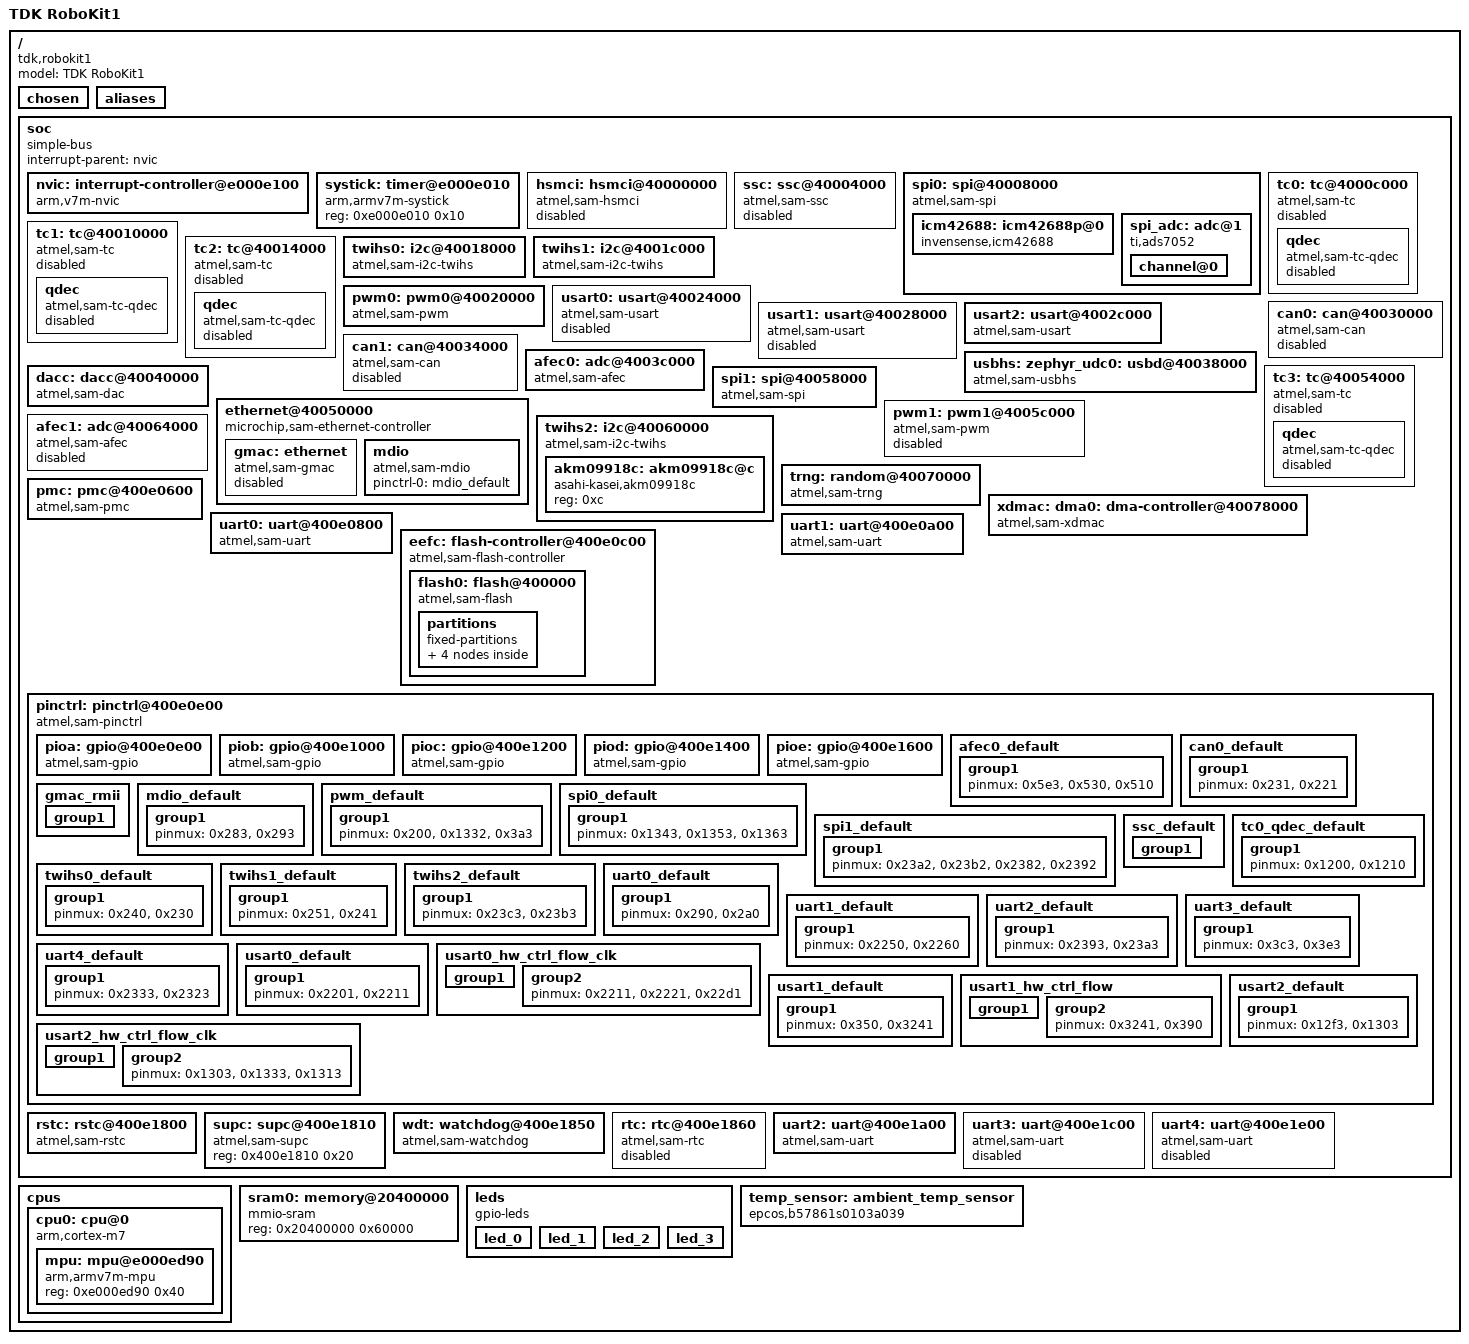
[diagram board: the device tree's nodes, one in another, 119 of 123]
/dts-v1/;

/* node '/' defined in zephyr/dts/common/skeleton.dtsi:9 */
/ {
	#address-cells = < 0x1 >;        /* in zephyr/dts/common/skeleton.dtsi:10 */
	#size-cells = < 0x1 >;           /* in zephyr/dts/common/skeleton.dtsi:11 */
	model = "TDK RoboKit1";          /* in zephyr/boards/tdk/robokit1/robokit1.dts:15 */
	compatible = "tdk,robokit1",
	             "atmel,same70q21b",
	             "atmel,same70";     /* in zephyr/boards/tdk/robokit1/robokit1.dts:16 */

	/* node '/chosen' defined in zephyr/dts/common/skeleton.dtsi:13 */
	chosen {
		zephyr,flash-controller = &eefc;          /* in zephyr/dts/arm/atmel/samx7x.dtsi:22 */
		zephyr,entropy = &trng;                   /* in zephyr/dts/arm/atmel/samx7x.dtsi:23 */
		zephyr,console = &uart2;                  /* in zephyr/boards/tdk/robokit1/robokit1-common.dtsi:19 */
		zephyr,shell-uart = &uart2;               /* in zephyr/boards/tdk/robokit1/robokit1-common.dtsi:20 */
		zephyr,sram = &sram0;                     /* in zephyr/boards/tdk/robokit1/robokit1-common.dtsi:21 */
		zephyr,flash = &flash0;                   /* in zephyr/boards/tdk/robokit1/robokit1-common.dtsi:22 */
		zephyr,code-partition = &slot0_partition; /* in zephyr/boards/tdk/robokit1/robokit1-common.dtsi:23 */
	};

	/* node '/aliases' defined in zephyr/dts/common/skeleton.dtsi:15 */
	aliases {
		watchdog0 = &wdt;             /* in zephyr/dts/arm/atmel/samx7x.dtsi:18 */
		led0 = &led_0;                /* in zephyr/boards/tdk/robokit1/robokit1-common.dtsi:11 */
		magn0 = &akm09918c;           /* in zephyr/boards/tdk/robokit1/robokit1-common.dtsi:12 */
		accel0 = &icm42688;           /* in zephyr/boards/tdk/robokit1/robokit1-common.dtsi:13 */
		die-temp0 = &icm42688;        /* in zephyr/boards/tdk/robokit1/robokit1-common.dtsi:14 */
		ambient-temp0 = &temp_sensor; /* in zephyr/boards/tdk/robokit1/robokit1-common.dtsi:15 */
	};

	/* node '/soc' defined in zephyr/dts/arm/armv7-m.dtsi:6 */
	soc {
		#address-cells = < 0x1 >;     /* in zephyr/dts/arm/armv7-m.dtsi:7 */
		#size-cells = < 0x1 >;        /* in zephyr/dts/arm/armv7-m.dtsi:8 */
		compatible = "simple-bus";    /* in zephyr/dts/arm/armv7-m.dtsi:9 */
		interrupt-parent = < &nvic >; /* in zephyr/dts/arm/armv7-m.dtsi:10 */
		ranges;                       /* in zephyr/dts/arm/armv7-m.dtsi:11 */

		/* node '/soc/interrupt-controller@e000e100' defined in zephyr/dts/arm/armv7-m.dtsi:13 */
		nvic: interrupt-controller@e000e100 {
			#address-cells = < 0x1 >;            /* in zephyr/dts/arm/armv7-m.dtsi:14 */
			compatible = "arm,v7m-nvic";         /* in zephyr/dts/arm/armv7-m.dtsi:15 */
			reg = < 0xe000e100 0xc00 >;          /* in zephyr/dts/arm/armv7-m.dtsi:16 */
			interrupt-controller;                /* in zephyr/dts/arm/armv7-m.dtsi:17 */
			#interrupt-cells = < 0x2 >;          /* in zephyr/dts/arm/armv7-m.dtsi:18 */
			arm,num-irq-priority-bits = < 0x3 >; /* in zephyr/dts/arm/atmel/samx7x.dtsi:488 */
			phandle = < 0x1 >;                   /* in zephyr/dts/arm/armv7-m.dtsi:10 */
		};

		/* node '/soc/timer@e000e010' defined in zephyr/dts/arm/armv7-m.dtsi:21 */
		systick: timer@e000e010 {
			compatible = "arm,armv7m-systick"; /* in zephyr/dts/arm/armv7-m.dtsi:22 */
			reg = < 0xe000e010 0x10 >;         /* in zephyr/dts/arm/armv7-m.dtsi:23 */
		};

		/* node '/soc/hsmci@40000000' defined in zephyr/dts/arm/atmel/samx7x.dtsi:49 */
		hsmci: hsmci@40000000 {
			compatible = "atmel,sam-hsmci"; /* in zephyr/dts/arm/atmel/samx7x.dtsi:50 */
			reg = < 0x40000000 0x4000 >;    /* in zephyr/dts/arm/atmel/samx7x.dtsi:51 */
			clocks = < &pmc 0x2 0x12 >;     /* in zephyr/dts/arm/atmel/samx7x.dtsi:52 */
			status = "disabled";            /* in zephyr/dts/arm/atmel/samx7x.dtsi:53 */
		};

		/* node '/soc/ssc@40004000' defined in zephyr/dts/arm/atmel/samx7x.dtsi:56 */
		ssc: ssc@40004000 {
			compatible = "atmel,sam-ssc"; /* in zephyr/dts/arm/atmel/samx7x.dtsi:57 */
			reg = < 0x40004000 0x4000 >;  /* in zephyr/dts/arm/atmel/samx7x.dtsi:58 */
			interrupts = < 0x16 0x0 >;    /* in zephyr/dts/arm/atmel/samx7x.dtsi:59 */
			clocks = < &pmc 0x2 0x16 >;   /* in zephyr/dts/arm/atmel/samx7x.dtsi:60 */
			status = "disabled";          /* in zephyr/dts/arm/atmel/samx7x.dtsi:61 */
		};

		/* node '/soc/spi@40008000' defined in zephyr/dts/arm/atmel/samx7x.dtsi:64 */
		spi0: spi@40008000 {
			compatible = "atmel,sam-spi";  /* in zephyr/dts/arm/atmel/samx7x.dtsi:65 */
			#address-cells = < 0x1 >;      /* in zephyr/dts/arm/atmel/samx7x.dtsi:66 */
			#size-cells = < 0x0 >;         /* in zephyr/dts/arm/atmel/samx7x.dtsi:67 */
			reg = < 0x40008000 0x4000 >;   /* in zephyr/dts/arm/atmel/samx7x.dtsi:68 */
			interrupts = < 0x15 0x0 >;     /* in zephyr/dts/arm/atmel/samx7x.dtsi:69 */
			clocks = < &pmc 0x2 0x15 >;    /* in zephyr/dts/arm/atmel/samx7x.dtsi:70 */
			pinctrl-0 = < &spi0_default >; /* in zephyr/boards/tdk/robokit1/robokit1-common.dtsi:100 */
			pinctrl-names = "default";     /* in zephyr/boards/tdk/robokit1/robokit1-common.dtsi:101 */
			dmas = < &xdmac 0x0 0x1 >,
			       < &xdmac 0x1 0x2 >;     /* in zephyr/boards/tdk/robokit1/robokit1-common.dtsi:102 */
			dma-names = "tx",
			            "rx";              /* in zephyr/boards/tdk/robokit1/robokit1-common.dtsi:103 */
			cs-gpios = < &pioa 0x1f 0x1 >,
			           < &pioc 0x1f 0x1 >; /* in zephyr/boards/tdk/robokit1/robokit1-common.dtsi:104 */
			status = "okay";               /* in zephyr/boards/tdk/robokit1/robokit1-common.dtsi:106 */

			/* node '/soc/spi@40008000/icm42688p@0' defined in zephyr/boards/tdk/robokit1/robokit1-common.dtsi:108 */
			icm42688: icm42688p@0 {
				compatible = "invensense,icm42688",
				             "invensense,icm4268x"; /* in zephyr/boards/tdk/robokit1/robokit1-common.dtsi:109 */
				reg = < 0x0 >;                      /* in zephyr/boards/tdk/robokit1/robokit1-common.dtsi:110 */
				int-gpios = < &pioc 0x5 0x0 >;      /* in zephyr/boards/tdk/robokit1/robokit1-common.dtsi:111 */
				spi-max-frequency = < 0x16e3600 >;  /* in zephyr/boards/tdk/robokit1/robokit1-common.dtsi:112 */
				accel-pwr-mode = < 0x3 >;           /* in zephyr/boards/tdk/robokit1/robokit1-common.dtsi:113 */
				accel-odr = < 0x5 >;                /* in zephyr/boards/tdk/robokit1/robokit1-common.dtsi:114 */
				accel-fs = < 0x0 >;                 /* in zephyr/boards/tdk/robokit1/robokit1-common.dtsi:115 */
				gyro-pwr-mode = < 0x3 >;            /* in zephyr/boards/tdk/robokit1/robokit1-common.dtsi:116 */
				gyro-odr = < 0x5 >;                 /* in zephyr/boards/tdk/robokit1/robokit1-common.dtsi:117 */
				gyro-fs = < 0x0 >;                  /* in zephyr/boards/tdk/robokit1/robokit1-common.dtsi:118 */
			};

			/* node '/soc/spi@40008000/adc@1' defined in zephyr/boards/tdk/robokit1/robokit1-common.dtsi:121 */
			spi_adc: adc@1 {
				compatible = "ti,ads7052";         /* in zephyr/boards/tdk/robokit1/robokit1-common.dtsi:122 */
				reg = < 0x1 >;                     /* in zephyr/boards/tdk/robokit1/robokit1-common.dtsi:123 */
				#io-channel-cells = < 0x1 >;       /* in zephyr/boards/tdk/robokit1/robokit1-common.dtsi:124 */
				#address-cells = < 0x1 >;          /* in zephyr/boards/tdk/robokit1/robokit1-common.dtsi:125 */
				#size-cells = < 0x0 >;             /* in zephyr/boards/tdk/robokit1/robokit1-common.dtsi:126 */
				spi-max-frequency = < 0x16e3600 >; /* in zephyr/boards/tdk/robokit1/robokit1-common.dtsi:127 */
				phandle = < 0x13 >;                /* in zephyr/boards/tdk/robokit1/robokit1-common.dtsi:52 */

				/* node '/soc/spi@40008000/adc@1/channel@0' defined in zephyr/boards/tdk/robokit1/robokit1-common.dtsi:129 */
				channel@0 {
					reg = < 0x0 >;                      /* in zephyr/boards/tdk/robokit1/robokit1-common.dtsi:130 */
					zephyr,gain = "ADC_GAIN_1";         /* in zephyr/boards/tdk/robokit1/robokit1-common.dtsi:131 */
					zephyr,reference = "ADC_REF_VDD_1"; /* in zephyr/boards/tdk/robokit1/robokit1-common.dtsi:132 */
					zephyr,vref-mv = < 0xce4 >;         /* in zephyr/boards/tdk/robokit1/robokit1-common.dtsi:133 */
					zephyr,acquisition-time = < 0x0 >;  /* in zephyr/boards/tdk/robokit1/robokit1-common.dtsi:134 */
					zephyr,resolution = < 0xe >;        /* in zephyr/boards/tdk/robokit1/robokit1-common.dtsi:135 */
				};
			};
		};

		/* node '/soc/tc@4000c000' defined in zephyr/dts/arm/atmel/samx7x.dtsi:74 */
		tc0: tc@4000c000 {
			compatible = "atmel,sam-tc";                 /* in zephyr/dts/arm/atmel/samx7x.dtsi:75 */
			reg = < 0x4000c000 0x100 >;                  /* in zephyr/dts/arm/atmel/samx7x.dtsi:76 */
			interrupts = < 0x17 0x0 0x18 0x0 0x19 0x0 >; /* in zephyr/dts/arm/atmel/samx7x.dtsi:77 */
			clocks = < &pmc 0x2 0x17 >,
			         < &pmc 0x2 0x18 >,
			         < &pmc 0x2 0x19 >;                  /* in zephyr/dts/arm/atmel/samx7x.dtsi:80 */
			status = "disabled";                         /* in zephyr/dts/arm/atmel/samx7x.dtsi:83 */

			/* node '/soc/tc@4000c000/qdec' defined in zephyr/dts/arm/atmel/samx7x.dtsi:85 */
			qdec {
				compatible = "atmel,sam-tc-qdec"; /* in zephyr/dts/arm/atmel/samx7x.dtsi:86 */
				status = "disabled";              /* in zephyr/dts/arm/atmel/samx7x.dtsi:87 */
			};
		};

		/* node '/soc/tc@40010000' defined in zephyr/dts/arm/atmel/samx7x.dtsi:91 */
		tc1: tc@40010000 {
			compatible = "atmel,sam-tc";                 /* in zephyr/dts/arm/atmel/samx7x.dtsi:92 */
			reg = < 0x40010000 0x100 >;                  /* in zephyr/dts/arm/atmel/samx7x.dtsi:93 */
			interrupts = < 0x1a 0x0 0x1b 0x0 0x1c 0x0 >; /* in zephyr/dts/arm/atmel/samx7x.dtsi:94 */
			clocks = < &pmc 0x2 0x1a >,
			         < &pmc 0x2 0x1b >,
			         < &pmc 0x2 0x1c >;                  /* in zephyr/dts/arm/atmel/samx7x.dtsi:97 */
			status = "disabled";                         /* in zephyr/dts/arm/atmel/samx7x.dtsi:100 */

			/* node '/soc/tc@40010000/qdec' defined in zephyr/dts/arm/atmel/samx7x.dtsi:102 */
			qdec {
				compatible = "atmel,sam-tc-qdec"; /* in zephyr/dts/arm/atmel/samx7x.dtsi:103 */
				status = "disabled";              /* in zephyr/dts/arm/atmel/samx7x.dtsi:104 */
			};
		};

		/* node '/soc/tc@40014000' defined in zephyr/dts/arm/atmel/samx7x.dtsi:108 */
		tc2: tc@40014000 {
			compatible = "atmel,sam-tc";                 /* in zephyr/dts/arm/atmel/samx7x.dtsi:109 */
			reg = < 0x40014000 0x100 >;                  /* in zephyr/dts/arm/atmel/samx7x.dtsi:110 */
			interrupts = < 0x2f 0x0 0x30 0x0 0x31 0x0 >; /* in zephyr/dts/arm/atmel/samx7x.dtsi:111 */
			clocks = < &pmc 0x2 0x2f >,
			         < &pmc 0x2 0x30 >,
			         < &pmc 0x2 0x31 >;                  /* in zephyr/dts/arm/atmel/samx7x.dtsi:114 */
			status = "disabled";                         /* in zephyr/dts/arm/atmel/samx7x.dtsi:117 */

			/* node '/soc/tc@40014000/qdec' defined in zephyr/dts/arm/atmel/samx7x.dtsi:119 */
			qdec {
				compatible = "atmel,sam-tc-qdec"; /* in zephyr/dts/arm/atmel/samx7x.dtsi:120 */
				status = "disabled";              /* in zephyr/dts/arm/atmel/samx7x.dtsi:121 */
			};
		};

		/* node '/soc/i2c@40018000' defined in zephyr/dts/arm/atmel/samx7x.dtsi:125 */
		twihs0: i2c@40018000 {
			compatible = "atmel,sam-i2c-twihs"; /* in zephyr/dts/arm/atmel/samx7x.dtsi:126 */
			clock-frequency = < 0x186a0 >;      /* in zephyr/dts/arm/atmel/samx7x.dtsi:127 */
			#address-cells = < 0x1 >;           /* in zephyr/dts/arm/atmel/samx7x.dtsi:128 */
			#size-cells = < 0x0 >;              /* in zephyr/dts/arm/atmel/samx7x.dtsi:129 */
			reg = < 0x40018000 0x12b >;         /* in zephyr/dts/arm/atmel/samx7x.dtsi:130 */
			interrupts = < 0x13 0x0 >;          /* in zephyr/dts/arm/atmel/samx7x.dtsi:131 */
			clocks = < &pmc 0x2 0x13 >;         /* in zephyr/dts/arm/atmel/samx7x.dtsi:132 */
			pinctrl-0 = < &twihs0_default >;    /* in zephyr/boards/tdk/robokit1/robokit1-common.dtsi:75 */
			pinctrl-names = "default";          /* in zephyr/boards/tdk/robokit1/robokit1-common.dtsi:76 */
			status = "okay";                    /* in zephyr/boards/tdk/robokit1/robokit1-common.dtsi:77 */
		};

		/* node '/soc/i2c@4001c000' defined in zephyr/dts/arm/atmel/samx7x.dtsi:136 */
		twihs1: i2c@4001c000 {
			compatible = "atmel,sam-i2c-twihs"; /* in zephyr/dts/arm/atmel/samx7x.dtsi:137 */
			clock-frequency = < 0x186a0 >;      /* in zephyr/dts/arm/atmel/samx7x.dtsi:138 */
			#address-cells = < 0x1 >;           /* in zephyr/dts/arm/atmel/samx7x.dtsi:139 */
			#size-cells = < 0x0 >;              /* in zephyr/dts/arm/atmel/samx7x.dtsi:140 */
			reg = < 0x4001c000 0x12b >;         /* in zephyr/dts/arm/atmel/samx7x.dtsi:141 */
			interrupts = < 0x14 0x0 >;          /* in zephyr/dts/arm/atmel/samx7x.dtsi:142 */
			clocks = < &pmc 0x2 0x14 >;         /* in zephyr/dts/arm/atmel/samx7x.dtsi:143 */
			pinctrl-0 = < &twihs1_default >;    /* in zephyr/boards/tdk/robokit1/robokit1-common.dtsi:81 */
			pinctrl-names = "default";          /* in zephyr/boards/tdk/robokit1/robokit1-common.dtsi:82 */
			status = "okay";                    /* in zephyr/boards/tdk/robokit1/robokit1-common.dtsi:83 */
		};

		/* node '/soc/pwm0@40020000' defined in zephyr/dts/arm/atmel/samx7x.dtsi:147 */
		pwm0: pwm0@40020000 {
			compatible = "atmel,sam-pwm"; /* in zephyr/dts/arm/atmel/samx7x.dtsi:148 */
			reg = < 0x40020000 0x4000 >;  /* in zephyr/dts/arm/atmel/samx7x.dtsi:149 */
			interrupts = < 0x1f 0x0 >;    /* in zephyr/dts/arm/atmel/samx7x.dtsi:150 */
			clocks = < &pmc 0x2 0x1f >;   /* in zephyr/dts/arm/atmel/samx7x.dtsi:151 */
			prescaler = < 0xa >;          /* in zephyr/dts/arm/atmel/samx7x.dtsi:153 */
			divider = < 0x1 >;            /* in zephyr/dts/arm/atmel/samx7x.dtsi:154 */
			#pwm-cells = < 0x3 >;         /* in zephyr/dts/arm/atmel/samx7x.dtsi:155 */
			pinctrl-0 = < &pwm_default >; /* in zephyr/boards/tdk/robokit1/robokit1-common.dtsi:190 */
			pinctrl-names = "default";    /* in zephyr/boards/tdk/robokit1/robokit1-common.dtsi:191 */
			status = "okay";              /* in zephyr/boards/tdk/robokit1/robokit1-common.dtsi:192 */
		};

		/* node '/soc/usart@40024000' defined in zephyr/dts/arm/atmel/samx7x.dtsi:158 */
		usart0: usart@40024000 {
			compatible = "atmel,sam-usart"; /* in zephyr/dts/arm/atmel/samx7x.dtsi:159 */
			reg = < 0x40024000 0x100 >;     /* in zephyr/dts/arm/atmel/samx7x.dtsi:160 */
			interrupts = < 0xd 0x0 >;       /* in zephyr/dts/arm/atmel/samx7x.dtsi:161 */
			clocks = < &pmc 0x2 0xd >;      /* in zephyr/dts/arm/atmel/samx7x.dtsi:162 */
			status = "disabled";            /* in zephyr/dts/arm/atmel/samx7x.dtsi:163 */
		};

		/* node '/soc/usart@40028000' defined in zephyr/dts/arm/atmel/samx7x.dtsi:166 */
		usart1: usart@40028000 {
			compatible = "atmel,sam-usart"; /* in zephyr/dts/arm/atmel/samx7x.dtsi:167 */
			reg = < 0x40028000 0x100 >;     /* in zephyr/dts/arm/atmel/samx7x.dtsi:168 */
			interrupts = < 0xe 0x0 >;       /* in zephyr/dts/arm/atmel/samx7x.dtsi:169 */
			clocks = < &pmc 0x2 0xe >;      /* in zephyr/dts/arm/atmel/samx7x.dtsi:170 */
			status = "disabled";            /* in zephyr/dts/arm/atmel/samx7x.dtsi:171 */
		};

		/* node '/soc/usart@4002c000' defined in zephyr/dts/arm/atmel/samx7x.dtsi:174 */
		usart2: usart@4002c000 {
			compatible = "atmel,sam-usart";  /* in zephyr/dts/arm/atmel/samx7x.dtsi:175 */
			reg = < 0x4002c000 0x100 >;      /* in zephyr/dts/arm/atmel/samx7x.dtsi:176 */
			interrupts = < 0xf 0x0 >;        /* in zephyr/dts/arm/atmel/samx7x.dtsi:177 */
			clocks = < &pmc 0x2 0xf >;       /* in zephyr/dts/arm/atmel/samx7x.dtsi:178 */
			current-speed = < 0x1c200 >;     /* in zephyr/boards/tdk/robokit1/robokit1-common.dtsi:169 */
			pinctrl-0 = < &usart2_default >; /* in zephyr/boards/tdk/robokit1/robokit1-common.dtsi:170 */
			pinctrl-names = "default";       /* in zephyr/boards/tdk/robokit1/robokit1-common.dtsi:171 */
			status = "okay";                 /* in zephyr/boards/tdk/robokit1/robokit1-common.dtsi:172 */
		};

		/* node '/soc/can@40030000' defined in zephyr/dts/arm/atmel/samx7x.dtsi:182 */
		can0: can@40030000 {
			compatible = "atmel,sam-can";                          /* in zephyr/dts/arm/atmel/samx7x.dtsi:183 */
			reg = < 0x40030000 0x100 >,
			      < 0x40088110 0x4 >;                              /* in zephyr/dts/arm/atmel/samx7x.dtsi:184 */
			reg-names = "m_can",
			            "dma_base";                                /* in zephyr/dts/arm/atmel/samx7x.dtsi:185 */
			interrupts = < 0x23 0x0 >,
			             < 0x24 0x0 >;                             /* in zephyr/dts/arm/atmel/samx7x.dtsi:186 */
			interrupt-names = "int0",
			                  "int1";                              /* in zephyr/dts/arm/atmel/samx7x.dtsi:187 */
			clocks = < &pmc 0x2 0x23 >;                            /* in zephyr/dts/arm/atmel/samx7x.dtsi:188 */
			divider = < 0x6 >;                                     /* in zephyr/dts/arm/atmel/samx7x.dtsi:189 */
			bosch,mram-cfg = < 0x0 0x1c 0x8 0x3 0x3 0x0 0x1 0x1 >; /* in zephyr/dts/arm/atmel/samx7x.dtsi:190 */
			status = "disabled";                                   /* in zephyr/dts/arm/atmel/samx7x.dtsi:191 */
		};

		/* node '/soc/can@40034000' defined in zephyr/dts/arm/atmel/samx7x.dtsi:194 */
		can1: can@40034000 {
			compatible = "atmel,sam-can";                          /* in zephyr/dts/arm/atmel/samx7x.dtsi:195 */
			reg = < 0x40034000 0x100 >,
			      < 0x40088114 0x4 >;                              /* in zephyr/dts/arm/atmel/samx7x.dtsi:196 */
			reg-names = "m_can",
			            "dma_base";                                /* in zephyr/dts/arm/atmel/samx7x.dtsi:197 */
			interrupts = < 0x25 0x0 >,
			             < 0x26 0x0 >;                             /* in zephyr/dts/arm/atmel/samx7x.dtsi:198 */
			interrupt-names = "int0",
			                  "int1";                              /* in zephyr/dts/arm/atmel/samx7x.dtsi:199 */
			clocks = < &pmc 0x2 0x25 >;                            /* in zephyr/dts/arm/atmel/samx7x.dtsi:200 */
			divider = < 0x6 >;                                     /* in zephyr/dts/arm/atmel/samx7x.dtsi:201 */
			bosch,mram-cfg = < 0x0 0x1c 0x8 0x3 0x3 0x0 0x1 0x1 >; /* in zephyr/dts/arm/atmel/samx7x.dtsi:202 */
			status = "disabled";                                   /* in zephyr/dts/arm/atmel/samx7x.dtsi:203 */
		};

		/* node '/soc/usbd@40038000' defined in zephyr/dts/arm/atmel/samx7x.dtsi:206 */
		usbhs: zephyr_udc0: usbd@40038000 {
			compatible = "atmel,sam-usbhs"; /* in zephyr/dts/arm/atmel/samx7x.dtsi:207 */
			reg = < 0x40038000 0x4000 >;    /* in zephyr/dts/arm/atmel/samx7x.dtsi:208 */
			interrupts = < 0x22 0x0 >;      /* in zephyr/dts/arm/atmel/samx7x.dtsi:209 */
			interrupt-names = "usbhs";      /* in zephyr/dts/arm/atmel/samx7x.dtsi:210 */
			maximum-speed = "high-speed";   /* in zephyr/dts/arm/atmel/samx7x.dtsi:211 */
			num-bidir-endpoints = < 0xa >;  /* in zephyr/dts/arm/atmel/samx7x.dtsi:212 */
			clocks = < &pmc 0x2 0x22 >;     /* in zephyr/dts/arm/atmel/samx7x.dtsi:213 */
			status = "okay";                /* in zephyr/boards/tdk/robokit1/robokit1-common.dtsi:180 */
		};

		/* node '/soc/adc@4003c000' defined in zephyr/dts/arm/atmel/samx7x.dtsi:217 */
		afec0: adc@4003c000 {
			compatible = "atmel,sam-afec";  /* in zephyr/dts/arm/atmel/samx7x.dtsi:218 */
			reg = < 0x4003c000 0x100 >;     /* in zephyr/dts/arm/atmel/samx7x.dtsi:219 */
			interrupts = < 0x1d 0x0 >;      /* in zephyr/dts/arm/atmel/samx7x.dtsi:220 */
			clocks = < &pmc 0x2 0x1d >;     /* in zephyr/dts/arm/atmel/samx7x.dtsi:221 */
			#io-channel-cells = < 0x1 >;    /* in zephyr/dts/arm/atmel/samx7x.dtsi:223 */
			pinctrl-0 = < &afec0_default >; /* in zephyr/boards/tdk/robokit1/robokit1-common.dtsi:65 */
			pinctrl-names = "default";      /* in zephyr/boards/tdk/robokit1/robokit1-common.dtsi:66 */
			status = "okay";                /* in zephyr/boards/tdk/robokit1/robokit1-common.dtsi:67 */
		};

		/* node '/soc/dacc@40040000' defined in zephyr/dts/arm/atmel/samx7x.dtsi:226 */
		dacc: dacc@40040000 {
			compatible = "atmel,sam-dac"; /* in zephyr/dts/arm/atmel/samx7x.dtsi:227 */
			reg = < 0x40040000 0x100 >;   /* in zephyr/dts/arm/atmel/samx7x.dtsi:228 */
			interrupts = < 0x1e 0x0 >;    /* in zephyr/dts/arm/atmel/samx7x.dtsi:229 */
			clocks = < &pmc 0x2 0x1e >;   /* in zephyr/dts/arm/atmel/samx7x.dtsi:230 */
			#io-channel-cells = < 0x1 >;  /* in zephyr/dts/arm/atmel/samx7x.dtsi:232 */
			status = "okay";              /* in zephyr/boards/tdk/robokit1/robokit1-common.dtsi:71 */
		};

		/* node '/soc/ethernet@40050000' defined in zephyr/dts/arm/atmel/samx7x.dtsi:235 */
		ethernet@40050000 {
			compatible = "microchip,sam-ethernet-controller"; /* in zephyr/dts/arm/atmel/samx7x.dtsi:236 */
			reg = < 0x40050000 0x4000 >;                      /* in zephyr/dts/arm/atmel/samx7x.dtsi:237 */
			clocks = < &pmc 0x2 0x27 >;                       /* in zephyr/dts/arm/atmel/samx7x.dtsi:238 */

			/* node '/soc/ethernet@40050000/ethernet' defined in zephyr/dts/arm/atmel/samx7x.dtsi:240 */
			gmac: ethernet {
				compatible = "atmel,sam-gmac";             /* in zephyr/dts/arm/atmel/samx7x.dtsi:241 */
				local-mac-address = [ 00 00 00 00 00 00 ]; /* in zephyr/dts/arm/atmel/samx7x.dtsi:245 */
				status = "disabled";                       /* in zephyr/dts/arm/atmel/samx7x.dtsi:246 */
				interrupts = < 0x27 0x0 >,
				             < 0x42 0x0 >,
				             < 0x43 0x0 >,
				             < 0x47 0x0 >,
				             < 0x48 0x0 >,
				             < 0x49 0x0 >;                 /* in zephyr/dts/arm/atmel/samx7xb.dtsi:10 */
				interrupt-names = "gmac",
				                  "q1",
				                  "q2",
				                  "q3",
				                  "q4",
				                  "q5";                    /* in zephyr/dts/arm/atmel/samx7xb.dtsi:11 */
				num-queues = < 0x6 >;                      /* in zephyr/dts/arm/atmel/samx7xb.dtsi:12 */
			};

			/* node '/soc/ethernet@40050000/mdio' defined in zephyr/dts/arm/atmel/samx7x.dtsi:249 */
			mdio: mdio {
				compatible = "atmel,sam-mdio"; /* in zephyr/dts/arm/atmel/samx7x.dtsi:250 */
				#address-cells = < 0x1 >;      /* in zephyr/dts/arm/atmel/samx7x.dtsi:252 */
				#size-cells = < 0x0 >;         /* in zephyr/dts/arm/atmel/samx7x.dtsi:253 */
				pinctrl-0 = < &mdio_default >; /* in zephyr/boards/tdk/robokit1/robokit1-common.dtsi:184 */
				pinctrl-names = "default";     /* in zephyr/boards/tdk/robokit1/robokit1-common.dtsi:185 */
				status = "okay";               /* in zephyr/boards/tdk/robokit1/robokit1-common.dtsi:186 */
			};
		};

		/* node '/soc/tc@40054000' defined in zephyr/dts/arm/atmel/samx7x.dtsi:257 */
		tc3: tc@40054000 {
			compatible = "atmel,sam-tc";                 /* in zephyr/dts/arm/atmel/samx7x.dtsi:258 */
			reg = < 0x40054000 0x100 >;                  /* in zephyr/dts/arm/atmel/samx7x.dtsi:259 */
			interrupts = < 0x32 0x0 0x33 0x0 0x34 0x0 >; /* in zephyr/dts/arm/atmel/samx7x.dtsi:260 */
			clocks = < &pmc 0x2 0x32 >,
			         < &pmc 0x2 0x33 >,
			         < &pmc 0x2 0x34 >;                  /* in zephyr/dts/arm/atmel/samx7x.dtsi:263 */
			status = "disabled";                         /* in zephyr/dts/arm/atmel/samx7x.dtsi:266 */

			/* node '/soc/tc@40054000/qdec' defined in zephyr/dts/arm/atmel/samx7x.dtsi:268 */
			qdec {
				compatible = "atmel,sam-tc-qdec"; /* in zephyr/dts/arm/atmel/samx7x.dtsi:269 */
				status = "disabled";              /* in zephyr/dts/arm/atmel/samx7x.dtsi:270 */
			};
		};

		/* node '/soc/spi@40058000' defined in zephyr/dts/arm/atmel/samx7x.dtsi:274 */
		spi1: spi@40058000 {
			compatible = "atmel,sam-spi";  /* in zephyr/dts/arm/atmel/samx7x.dtsi:275 */
			#address-cells = < 0x1 >;      /* in zephyr/dts/arm/atmel/samx7x.dtsi:276 */
			#size-cells = < 0x0 >;         /* in zephyr/dts/arm/atmel/samx7x.dtsi:277 */
			reg = < 0x40058000 0x4000 >;   /* in zephyr/dts/arm/atmel/samx7x.dtsi:278 */
			interrupts = < 0x2a 0x0 >;     /* in zephyr/dts/arm/atmel/samx7x.dtsi:279 */
			clocks = < &pmc 0x2 0x2a >;    /* in zephyr/dts/arm/atmel/samx7x.dtsi:280 */
			pinctrl-0 = < &spi1_default >; /* in zephyr/boards/tdk/robokit1/robokit1-common.dtsi:141 */
			pinctrl-names = "default";     /* in zephyr/boards/tdk/robokit1/robokit1-common.dtsi:142 */
			cs-gpios = < &pioc 0x19 0x1 >; /* in zephyr/boards/tdk/robokit1/robokit1-common.dtsi:143 */
			status = "okay";               /* in zephyr/boards/tdk/robokit1/robokit1-common.dtsi:144 */
		};

		/* node '/soc/pwm1@4005c000' defined in zephyr/dts/arm/atmel/samx7x.dtsi:284 */
		pwm1: pwm1@4005c000 {
			compatible = "atmel,sam-pwm"; /* in zephyr/dts/arm/atmel/samx7x.dtsi:285 */
			reg = < 0x4005c000 0x4000 >;  /* in zephyr/dts/arm/atmel/samx7x.dtsi:286 */
			interrupts = < 0x3c 0x0 >;    /* in zephyr/dts/arm/atmel/samx7x.dtsi:287 */
			clocks = < &pmc 0x2 0x3c >;   /* in zephyr/dts/arm/atmel/samx7x.dtsi:288 */
			status = "disabled";          /* in zephyr/dts/arm/atmel/samx7x.dtsi:289 */
			prescaler = < 0xa >;          /* in zephyr/dts/arm/atmel/samx7x.dtsi:290 */
			divider = < 0x1 >;            /* in zephyr/dts/arm/atmel/samx7x.dtsi:291 */
			#pwm-cells = < 0x3 >;         /* in zephyr/dts/arm/atmel/samx7x.dtsi:292 */
		};

		/* node '/soc/i2c@40060000' defined in zephyr/dts/arm/atmel/samx7x.dtsi:295 */
		twihs2: i2c@40060000 {
			compatible = "atmel,sam-i2c-twihs"; /* in zephyr/dts/arm/atmel/samx7x.dtsi:296 */
			clock-frequency = < 0x186a0 >;      /* in zephyr/dts/arm/atmel/samx7x.dtsi:297 */
			#address-cells = < 0x1 >;           /* in zephyr/dts/arm/atmel/samx7x.dtsi:298 */
			#size-cells = < 0x0 >;              /* in zephyr/dts/arm/atmel/samx7x.dtsi:299 */
			reg = < 0x40060000 0x12b >;         /* in zephyr/dts/arm/atmel/samx7x.dtsi:300 */
			interrupts = < 0x29 0x0 >;          /* in zephyr/dts/arm/atmel/samx7x.dtsi:301 */
			clocks = < &pmc 0x2 0x29 >;         /* in zephyr/dts/arm/atmel/samx7x.dtsi:302 */
			pinctrl-0 = < &twihs2_default >;    /* in zephyr/boards/tdk/robokit1/robokit1-common.dtsi:87 */
			pinctrl-names = "default";          /* in zephyr/boards/tdk/robokit1/robokit1-common.dtsi:88 */
			status = "okay";                    /* in zephyr/boards/tdk/robokit1/robokit1-common.dtsi:89 */

			/* node '/soc/i2c@40060000/akm09918c@c' defined in zephyr/boards/tdk/robokit1/robokit1-common.dtsi:91 */
			akm09918c: akm09918c@c {
				compatible = "asahi-kasei,akm09918c"; /* in zephyr/boards/tdk/robokit1/robokit1-common.dtsi:92 */
				reg = < 0xc >;                        /* in zephyr/boards/tdk/robokit1/robokit1-common.dtsi:93 */
			};
		};

		/* node '/soc/adc@40064000' defined in zephyr/dts/arm/atmel/samx7x.dtsi:306 */
		afec1: adc@40064000 {
			compatible = "atmel,sam-afec"; /* in zephyr/dts/arm/atmel/samx7x.dtsi:307 */
			reg = < 0x40064000 0x100 >;    /* in zephyr/dts/arm/atmel/samx7x.dtsi:308 */
			interrupts = < 0x28 0x0 >;     /* in zephyr/dts/arm/atmel/samx7x.dtsi:309 */
			clocks = < &pmc 0x2 0x28 >;    /* in zephyr/dts/arm/atmel/samx7x.dtsi:310 */
			status = "disabled";           /* in zephyr/dts/arm/atmel/samx7x.dtsi:311 */
			#io-channel-cells = < 0x1 >;   /* in zephyr/dts/arm/atmel/samx7x.dtsi:312 */
		};

		/* node '/soc/random@40070000' defined in zephyr/dts/arm/atmel/samx7x.dtsi:315 */
		trng: random@40070000 {
			compatible = "atmel,sam-trng"; /* in zephyr/dts/arm/atmel/samx7x.dtsi:316 */
			reg = < 0x40070000 0x4000 >;   /* in zephyr/dts/arm/atmel/samx7x.dtsi:317 */
			interrupts = < 0x39 0x0 >;     /* in zephyr/dts/arm/atmel/samx7x.dtsi:318 */
			clocks = < &pmc 0x2 0x39 >;    /* in zephyr/dts/arm/atmel/samx7x.dtsi:319 */
			status = "okay";               /* in zephyr/dts/arm/atmel/samx7x.dtsi:320 */
		};

		/* node '/soc/dma-controller@40078000' defined in zephyr/dts/arm/atmel/samx7x.dtsi:323 */
		xdmac: dma0: dma-controller@40078000 {
			compatible = "atmel,sam-xdmac"; /* in zephyr/dts/arm/atmel/samx7x.dtsi:324 */
			reg = < 0x40078000 0x400 >;     /* in zephyr/dts/arm/atmel/samx7x.dtsi:325 */
			interrupts = < 0x3a 0x0 >;      /* in zephyr/dts/arm/atmel/samx7x.dtsi:326 */
			clocks = < &pmc 0x2 0x3a >;     /* in zephyr/dts/arm/atmel/samx7x.dtsi:327 */
			#dma-cells = < 0x2 >;           /* in zephyr/dts/arm/atmel/samx7x.dtsi:328 */
			status = "okay";                /* in zephyr/boards/tdk/robokit1/robokit1-common.dtsi:196 */
			phandle = < 0x4 >;              /* in zephyr/boards/tdk/robokit1/robokit1-common.dtsi:102 */
		};

		/* node '/soc/pmc@400e0600' defined in zephyr/dts/arm/atmel/samx7x.dtsi:332 */
		pmc: pmc@400e0600 {
			compatible = "atmel,sam-pmc"; /* in zephyr/dts/arm/atmel/samx7x.dtsi:333 */
			reg = < 0x400e0600 0x200 >;   /* in zephyr/dts/arm/atmel/samx7x.dtsi:334 */
			interrupts = < 0x5 0x0 >;     /* in zephyr/dts/arm/atmel/samx7x.dtsi:335 */
			#clock-cells = < 0x2 >;       /* in zephyr/dts/arm/atmel/samx7x.dtsi:336 */
			status = "okay";              /* in zephyr/dts/arm/atmel/samx7x.dtsi:337 */
			phandle = < 0x2 >;            /* in zephyr/dts/arm/atmel/samx7x.dtsi:52 */
		};

		/* node '/soc/uart@400e0800' defined in zephyr/dts/arm/atmel/samx7x.dtsi:340 */
		uart0: uart@400e0800 {
			compatible = "atmel,sam-uart";  /* in zephyr/dts/arm/atmel/samx7x.dtsi:341 */
			reg = < 0x400e0800 0x100 >;     /* in zephyr/dts/arm/atmel/samx7x.dtsi:342 */
			interrupts = < 0x7 0x1 >;       /* in zephyr/dts/arm/atmel/samx7x.dtsi:343 */
			clocks = < &pmc 0x2 0x7 >;      /* in zephyr/dts/arm/atmel/samx7x.dtsi:344 */
			current-speed = < 0x1c200 >;    /* in zephyr/boards/tdk/robokit1/robokit1-common.dtsi:148 */
			pinctrl-0 = < &uart0_default >; /* in zephyr/boards/tdk/robokit1/robokit1-common.dtsi:149 */
			pinctrl-names = "default";      /* in zephyr/boards/tdk/robokit1/robokit1-common.dtsi:150 */
			status = "okay";                /* in zephyr/boards/tdk/robokit1/robokit1-common.dtsi:151 */
		};

		/* node '/soc/uart@400e0a00' defined in zephyr/dts/arm/atmel/samx7x.dtsi:348 */
		uart1: uart@400e0a00 {
			compatible = "atmel,sam-uart";  /* in zephyr/dts/arm/atmel/samx7x.dtsi:349 */
			reg = < 0x400e0a00 0x100 >;     /* in zephyr/dts/arm/atmel/samx7x.dtsi:350 */
			interrupts = < 0x8 0x1 >;       /* in zephyr/dts/arm/atmel/samx7x.dtsi:351 */
			clocks = < &pmc 0x2 0x8 >;      /* in zephyr/dts/arm/atmel/samx7x.dtsi:352 */
			current-speed = < 0x1c200 >;    /* in zephyr/boards/tdk/robokit1/robokit1-common.dtsi:155 */
			pinctrl-0 = < &uart1_default >; /* in zephyr/boards/tdk/robokit1/robokit1-common.dtsi:156 */
			pinctrl-names = "default";      /* in zephyr/boards/tdk/robokit1/robokit1-common.dtsi:157 */
			status = "okay";                /* in zephyr/boards/tdk/robokit1/robokit1-common.dtsi:158 */
		};

		/* node '/soc/flash-controller@400e0c00' defined in zephyr/dts/arm/atmel/samx7x.dtsi:356 */
		eefc: flash-controller@400e0c00 {
			compatible = "atmel,sam-flash-controller"; /* in zephyr/dts/arm/atmel/samx7x.dtsi:357 */
			reg = < 0x400e0c00 0x200 >;                /* in zephyr/dts/arm/atmel/samx7x.dtsi:358 */
			interrupts = < 0x6 0x0 >;                  /* in zephyr/dts/arm/atmel/samx7x.dtsi:359 */
			clocks = < &pmc 0x2 0x6 >;                 /* in zephyr/dts/arm/atmel/samx7x.dtsi:360 */
			#address-cells = < 0x1 >;                  /* in zephyr/dts/arm/atmel/samx7x.dtsi:362 */
			#size-cells = < 0x1 >;                     /* in zephyr/dts/arm/atmel/samx7x.dtsi:363 */
			#erase-block-cells = < 0x2 >;              /* in zephyr/dts/arm/atmel/samx7x.dtsi:364 */
			phandle = < 0x11 >;                        /* in zephyr/dts/arm/atmel/samx7xx21.dtsi:19 */

			/* node '/soc/flash-controller@400e0c00/flash@400000' defined in zephyr/dts/arm/atmel/samx7x.dtsi:366 */
			flash0: flash@400000 {
				compatible = "atmel,sam-flash",
				             "soc-nv-flash";          /* in zephyr/dts/arm/atmel/samx7x.dtsi:367 */
				write-block-size = < 0x10 >;          /* in zephyr/dts/arm/atmel/samx7x.dtsi:368 */
				erase-block-size = < 0x2000 >;        /* in zephyr/dts/arm/atmel/samx7x.dtsi:369 */
				reg = < 0x400000 0x200000 >;          /* in zephyr/dts/arm/atmel/samx7xx21.dtsi:18 */
				erase-blocks = < &eefc 0x8 0x800 >,
				               < &eefc 0xfe 0x2000 >; /* in zephyr/dts/arm/atmel/samx7xx21.dtsi:19 */

				/* node '/soc/flash-controller@400e0c00/flash@400000/partitions' defined in zephyr/boards/tdk/robokit1/robokit1-common.dtsi:200 */
				partitions {
					compatible = "fixed-partitions"; /* in zephyr/boards/tdk/robokit1/robokit1-common.dtsi:201 */
					#address-cells = < 0x1 >;        /* in zephyr/boards/tdk/robokit1/robokit1-common.dtsi:202 */
					#size-cells = < 0x1 >;           /* in zephyr/boards/tdk/robokit1/robokit1-common.dtsi:203 */

					/* node '/soc/flash-controller@400e0c00/flash@400000/partitions/partition@0' defined in zephyr/boards/tdk/robokit1/robokit1-common.dtsi:209 */
					boot_partition: partition@0 {
						label = "mcuboot";     /* in zephyr/boards/tdk/robokit1/robokit1-common.dtsi:210 */
						reg = < 0x0 0x10000 >; /* in zephyr/boards/tdk/robokit1/robokit1-common.dtsi:211 */
						read-only;             /* in zephyr/boards/tdk/robokit1/robokit1-common.dtsi:212 */
					};

					/* node '/soc/flash-controller@400e0c00/flash@400000/partitions/partition@20000' defined in zephyr/boards/tdk/robokit1/robokit1-common.dtsi:216 */
					slot0_partition: partition@20000 {
						label = "image-0";         /* in zephyr/boards/tdk/robokit1/robokit1-common.dtsi:217 */
						reg = < 0x20000 0xe0000 >; /* in zephyr/boards/tdk/robokit1/robokit1-common.dtsi:218 */
					};

					/* node '/soc/flash-controller@400e0c00/flash@400000/partitions/partition@100000' defined in zephyr/boards/tdk/robokit1/robokit1-common.dtsi:222 */
					slot1_partition: partition@100000 {
						label = "image-1";          /* in zephyr/boards/tdk/robokit1/robokit1-common.dtsi:223 */
						reg = < 0x100000 0xe0000 >; /* in zephyr/boards/tdk/robokit1/robokit1-common.dtsi:224 */
					};

					/* node '/soc/flash-controller@400e0c00/flash@400000/partitions/partition@1e0000' defined in zephyr/boards/tdk/robokit1/robokit1-common.dtsi:228 */
					scratch_partition: partition@1e0000 {
						label = "image-scratch";    /* in zephyr/boards/tdk/robokit1/robokit1-common.dtsi:229 */
						reg = < 0x1e0000 0x20000 >; /* in zephyr/boards/tdk/robokit1/robokit1-common.dtsi:230 */
					};
				};
			};
		};

		/* node '/soc/pinctrl@400e0e00' defined in zephyr/dts/arm/atmel/samx7x.dtsi:373 */
		pinctrl: pinctrl@400e0e00 {
			compatible = "atmel,sam-pinctrl";         /* in zephyr/dts/arm/atmel/samx7x.dtsi:374 */
			#address-cells = < 0x1 >;                 /* in zephyr/dts/arm/atmel/samx7x.dtsi:375 */
			#size-cells = < 0x1 >;                    /* in zephyr/dts/arm/atmel/samx7x.dtsi:376 */
			ranges = < 0x400e0e00 0x400e0e00 0xa00 >; /* in zephyr/dts/arm/atmel/samx7x.dtsi:377 */

			/* node '/soc/pinctrl@400e0e00/gpio@400e0e00' defined in zephyr/dts/arm/atmel/samx7x.dtsi:379 */
			pioa: gpio@400e0e00 {
				compatible = "atmel,sam-gpio"; /* in zephyr/dts/arm/atmel/samx7x.dtsi:380 */
				reg = < 0x400e0e00 0x190 >;    /* in zephyr/dts/arm/atmel/samx7x.dtsi:381 */
				interrupts = < 0xa 0x1 >;      /* in zephyr/dts/arm/atmel/samx7x.dtsi:382 */
				clocks = < &pmc 0x2 0xa >;     /* in zephyr/dts/arm/atmel/samx7x.dtsi:383 */
				gpio-controller;               /* in zephyr/dts/arm/atmel/samx7x.dtsi:384 */
				#gpio-cells = < 0x2 >;         /* in zephyr/dts/arm/atmel/samx7x.dtsi:385 */
				#atmel,pin-cells = < 0x2 >;    /* in zephyr/dts/arm/atmel/samx7x.dtsi:386 */
				phandle = < 0x5 >;             /* in zephyr/boards/tdk/robokit1/robokit1-common.dtsi:104 */
			};

			/* node '/soc/pinctrl@400e0e00/gpio@400e1000' defined in zephyr/dts/arm/atmel/samx7x.dtsi:389 */
			piob: gpio@400e1000 {
				compatible = "atmel,sam-gpio"; /* in zephyr/dts/arm/atmel/samx7x.dtsi:390 */
				reg = < 0x400e1000 0x190 >;    /* in zephyr/dts/arm/atmel/samx7x.dtsi:391 */
				interrupts = < 0xb 0x1 >;      /* in zephyr/dts/arm/atmel/samx7x.dtsi:392 */
				clocks = < &pmc 0x2 0xb >;     /* in zephyr/dts/arm/atmel/samx7x.dtsi:393 */
				gpio-controller;               /* in zephyr/dts/arm/atmel/samx7x.dtsi:394 */
				#gpio-cells = < 0x2 >;         /* in zephyr/dts/arm/atmel/samx7x.dtsi:395 */
				#atmel,pin-cells = < 0x2 >;    /* in zephyr/dts/arm/atmel/samx7x.dtsi:396 */
			};

			/* node '/soc/pinctrl@400e0e00/gpio@400e1200' defined in zephyr/dts/arm/atmel/samx7x.dtsi:399 */
			pioc: gpio@400e1200 {
				compatible = "atmel,sam-gpio"; /* in zephyr/dts/arm/atmel/samx7x.dtsi:400 */
				reg = < 0x400e1200 0x190 >;    /* in zephyr/dts/arm/atmel/samx7x.dtsi:401 */
				interrupts = < 0xc 0x1 >;      /* in zephyr/dts/arm/atmel/samx7x.dtsi:402 */
				clocks = < &pmc 0x2 0xc >;     /* in zephyr/dts/arm/atmel/samx7x.dtsi:403 */
				gpio-controller;               /* in zephyr/dts/arm/atmel/samx7x.dtsi:404 */
				#gpio-cells = < 0x2 >;         /* in zephyr/dts/arm/atmel/samx7x.dtsi:405 */
				#atmel,pin-cells = < 0x2 >;    /* in zephyr/dts/arm/atmel/samx7x.dtsi:406 */
				phandle = < 0x6 >;             /* in zephyr/boards/tdk/robokit1/robokit1-common.dtsi:104 */
			};

			/* node '/soc/pinctrl@400e0e00/gpio@400e1400' defined in zephyr/dts/arm/atmel/samx7x.dtsi:409 */
			piod: gpio@400e1400 {
				compatible = "atmel,sam-gpio"; /* in zephyr/dts/arm/atmel/samx7x.dtsi:410 */
				reg = < 0x400e1400 0x190 >;    /* in zephyr/dts/arm/atmel/samx7x.dtsi:411 */
				interrupts = < 0x10 0x1 >;     /* in zephyr/dts/arm/atmel/samx7x.dtsi:412 */
				clocks = < &pmc 0x2 0x10 >;    /* in zephyr/dts/arm/atmel/samx7x.dtsi:413 */
				gpio-controller;               /* in zephyr/dts/arm/atmel/samx7x.dtsi:414 */
				#gpio-cells = < 0x2 >;         /* in zephyr/dts/arm/atmel/samx7x.dtsi:415 */
				#atmel,pin-cells = < 0x2 >;    /* in zephyr/dts/arm/atmel/samx7x.dtsi:416 */
			};

			/* node '/soc/pinctrl@400e0e00/gpio@400e1600' defined in zephyr/dts/arm/atmel/samx7x.dtsi:419 */
			pioe: gpio@400e1600 {
				compatible = "atmel,sam-gpio"; /* in zephyr/dts/arm/atmel/samx7x.dtsi:420 */
				reg = < 0x400e1600 0x190 >;    /* in zephyr/dts/arm/atmel/samx7x.dtsi:421 */
				interrupts = < 0x11 0x1 >;     /* in zephyr/dts/arm/atmel/samx7x.dtsi:422 */
				clocks = < &pmc 0x2 0x11 >;    /* in zephyr/dts/arm/atmel/samx7x.dtsi:423 */
				gpio-controller;               /* in zephyr/dts/arm/atmel/samx7x.dtsi:424 */
				#gpio-cells = < 0x2 >;         /* in zephyr/dts/arm/atmel/samx7x.dtsi:425 */
				#atmel,pin-cells = < 0x2 >;    /* in zephyr/dts/arm/atmel/samx7x.dtsi:426 */
			};

			/* node '/soc/pinctrl@400e0e00/afec0_default' defined in zephyr/boards/tdk/robokit1/robokit1-pinctrl.dtsi:9 */
			afec0_default: afec0_default {
				phandle = < 0xb >; /* in zephyr/boards/tdk/robokit1/robokit1-common.dtsi:65 */

				/* node '/soc/pinctrl@400e0e00/afec0_default/group1' defined in zephyr/boards/tdk/robokit1/robokit1-pinctrl.dtsi:10 */
				group1 {
					pinmux = < 0x5e3 >,
					         < 0x530 >,
					         < 0x510 >; /* in zephyr/boards/tdk/robokit1/robokit1-pinctrl.dtsi:11 */
				};
			};

			/* node '/soc/pinctrl@400e0e00/can0_default' defined in zephyr/boards/tdk/robokit1/robokit1-pinctrl.dtsi:17 */
			can0_default: can0_default {

				/* node '/soc/pinctrl@400e0e00/can0_default/group1' defined in zephyr/boards/tdk/robokit1/robokit1-pinctrl.dtsi:18 */
				group1 {
					pinmux = < 0x231 >,
					         < 0x221 >; /* in zephyr/boards/tdk/robokit1/robokit1-pinctrl.dtsi:19 */
				};
			};

			/* node '/soc/pinctrl@400e0e00/gmac_rmii' defined in zephyr/boards/tdk/robokit1/robokit1-pinctrl.dtsi:24 */
			gmac_rmii: gmac_rmii {

				/* node '/soc/pinctrl@400e0e00/gmac_rmii/group1' defined in zephyr/boards/tdk/robokit1/robokit1-pinctrl.dtsi:25 */
				group1 {
					pinmux = < 0x203 >,
					         < 0x213 >,
					         < 0x223 >,
					         < 0x233 >,
					         < 0x243 >,
					         < 0x253 >,
					         < 0x263 >,
					         < 0x273 >; /* in zephyr/boards/tdk/robokit1/robokit1-pinctrl.dtsi:26 */
				};
			};

			/* node '/soc/pinctrl@400e0e00/mdio_default' defined in zephyr/boards/tdk/robokit1/robokit1-pinctrl.dtsi:37 */
			mdio_default: mdio_default {
				phandle = < 0xc >; /* in zephyr/boards/tdk/robokit1/robokit1-common.dtsi:184 */

				/* node '/soc/pinctrl@400e0e00/mdio_default/group1' defined in zephyr/boards/tdk/robokit1/robokit1-pinctrl.dtsi:38 */
				group1 {
					pinmux = < 0x283 >,
					         < 0x293 >; /* in zephyr/boards/tdk/robokit1/robokit1-pinctrl.dtsi:39 */
				};
			};

			/* node '/soc/pinctrl@400e0e00/pwm_default' defined in zephyr/boards/tdk/robokit1/robokit1-pinctrl.dtsi:44 */
			pwm_default: pwm_default {
				phandle = < 0x9 >; /* in zephyr/boards/tdk/robokit1/robokit1-common.dtsi:190 */

				/* node '/soc/pinctrl@400e0e00/pwm_default/group1' defined in zephyr/boards/tdk/robokit1/robokit1-pinctrl.dtsi:45 */
				group1 {
					pinmux = < 0x200 >,
					         < 0x1332 >,
					         < 0x3a3 >;  /* in zephyr/boards/tdk/robokit1/robokit1-pinctrl.dtsi:46 */
				};
			};

			/* node '/soc/pinctrl@400e0e00/spi0_default' defined in zephyr/boards/tdk/robokit1/robokit1-pinctrl.dtsi:52 */
			spi0_default: spi0_default {
				phandle = < 0x3 >; /* in zephyr/boards/tdk/robokit1/robokit1-common.dtsi:100 */

				/* node '/soc/pinctrl@400e0e00/spi0_default/group1' defined in zephyr/boards/tdk/robokit1/robokit1-pinctrl.dtsi:53 */
				group1 {
					pinmux = < 0x1343 >,
					         < 0x1353 >,
					         < 0x1363 >; /* in zephyr/boards/tdk/robokit1/robokit1-pinctrl.dtsi:54 */
				};
			};

			/* node '/soc/pinctrl@400e0e00/spi1_default' defined in zephyr/boards/tdk/robokit1/robokit1-pinctrl.dtsi:60 */
			spi1_default: spi1_default {
				phandle = < 0xd >; /* in zephyr/boards/tdk/robokit1/robokit1-common.dtsi:141 */

				/* node '/soc/pinctrl@400e0e00/spi1_default/group1' defined in zephyr/boards/tdk/robokit1/robokit1-pinctrl.dtsi:61 */
				group1 {
					pinmux = < 0x23a2 >,
					         < 0x23b2 >,
					         < 0x2382 >,
					         < 0x2392 >; /* in zephyr/boards/tdk/robokit1/robokit1-pinctrl.dtsi:62 */
				};
			};

			/* node '/soc/pinctrl@400e0e00/ssc_default' defined in zephyr/boards/tdk/robokit1/robokit1-pinctrl.dtsi:69 */
			ssc_default: ssc_default {

				/* node '/soc/pinctrl@400e0e00/ssc_default/group1' defined in zephyr/boards/tdk/robokit1/robokit1-pinctrl.dtsi:70 */
				group1 {
					pinmux = < 0x1383 >,
					         < 0x360 >,
					         < 0x22a0 >,
					         < 0x3201 >,
					         < 0x3211 >,
					         < 0x3251 >; /* in zephyr/boards/tdk/robokit1/robokit1-pinctrl.dtsi:71 */
				};
			};

			/* node '/soc/pinctrl@400e0e00/tc0_qdec_default' defined in zephyr/boards/tdk/robokit1/robokit1-pinctrl.dtsi:80 */
			tc0_qdec_default: tc0_qdec_default {

				/* node '/soc/pinctrl@400e0e00/tc0_qdec_default/group1' defined in zephyr/boards/tdk/robokit1/robokit1-pinctrl.dtsi:81 */
				group1 {
					pinmux = < 0x1200 >,
					         < 0x1210 >; /* in zephyr/boards/tdk/robokit1/robokit1-pinctrl.dtsi:82 */
				};
			};

			/* node '/soc/pinctrl@400e0e00/twihs0_default' defined in zephyr/boards/tdk/robokit1/robokit1-pinctrl.dtsi:87 */
			twihs0_default: twihs0_default {
				phandle = < 0x7 >; /* in zephyr/boards/tdk/robokit1/robokit1-common.dtsi:75 */

				/* node '/soc/pinctrl@400e0e00/twihs0_default/group1' defined in zephyr/boards/tdk/robokit1/robokit1-pinctrl.dtsi:88 */
				group1 {
					pinmux = < 0x240 >,
					         < 0x230 >; /* in zephyr/boards/tdk/robokit1/robokit1-pinctrl.dtsi:89 */
				};
			};

			/* node '/soc/pinctrl@400e0e00/twihs1_default' defined in zephyr/boards/tdk/robokit1/robokit1-pinctrl.dtsi:94 */
			twihs1_default: twihs1_default {
				phandle = < 0x8 >; /* in zephyr/boards/tdk/robokit1/robokit1-common.dtsi:81 */

				/* node '/soc/pinctrl@400e0e00/twihs1_default/group1' defined in zephyr/boards/tdk/robokit1/robokit1-pinctrl.dtsi:95 */
				group1 {
					pinmux = < 0x251 >,
					         < 0x241 >; /* in zephyr/boards/tdk/robokit1/robokit1-pinctrl.dtsi:96 */
				};
			};

			/* node '/soc/pinctrl@400e0e00/twihs2_default' defined in zephyr/boards/tdk/robokit1/robokit1-pinctrl.dtsi:101 */
			twihs2_default: twihs2_default {
				phandle = < 0xe >; /* in zephyr/boards/tdk/robokit1/robokit1-common.dtsi:87 */

				/* node '/soc/pinctrl@400e0e00/twihs2_default/group1' defined in zephyr/boards/tdk/robokit1/robokit1-pinctrl.dtsi:102 */
				group1 {
					pinmux = < 0x23c3 >,
					         < 0x23b3 >; /* in zephyr/boards/tdk/robokit1/robokit1-pinctrl.dtsi:103 */
				};
			};

			/* node '/soc/pinctrl@400e0e00/uart0_default' defined in zephyr/boards/tdk/robokit1/robokit1-pinctrl.dtsi:108 */
			uart0_default: uart0_default {
				phandle = < 0xf >; /* in zephyr/boards/tdk/robokit1/robokit1-common.dtsi:149 */

				/* node '/soc/pinctrl@400e0e00/uart0_default/group1' defined in zephyr/boards/tdk/robokit1/robokit1-pinctrl.dtsi:109 */
				group1 {
					pinmux = < 0x290 >,
					         < 0x2a0 >; /* in zephyr/boards/tdk/robokit1/robokit1-pinctrl.dtsi:110 */
				};
			};

			/* node '/soc/pinctrl@400e0e00/uart1_default' defined in zephyr/boards/tdk/robokit1/robokit1-pinctrl.dtsi:115 */
			uart1_default: uart1_default {
				phandle = < 0x10 >; /* in zephyr/boards/tdk/robokit1/robokit1-common.dtsi:156 */

				/* node '/soc/pinctrl@400e0e00/uart1_default/group1' defined in zephyr/boards/tdk/robokit1/robokit1-pinctrl.dtsi:116 */
				group1 {
					pinmux = < 0x2250 >,
					         < 0x2260 >; /* in zephyr/boards/tdk/robokit1/robokit1-pinctrl.dtsi:117 */
				};
			};

			/* node '/soc/pinctrl@400e0e00/uart2_default' defined in zephyr/boards/tdk/robokit1/robokit1-pinctrl.dtsi:122 */
			uart2_default: uart2_default {
				phandle = < 0x12 >; /* in zephyr/boards/tdk/robokit1/robokit1-common.dtsi:163 */

				/* node '/soc/pinctrl@400e0e00/uart2_default/group1' defined in zephyr/boards/tdk/robokit1/robokit1-pinctrl.dtsi:123 */
				group1 {
					pinmux = < 0x2393 >,
					         < 0x23a3 >; /* in zephyr/boards/tdk/robokit1/robokit1-pinctrl.dtsi:124 */
				};
			};

			/* node '/soc/pinctrl@400e0e00/uart3_default' defined in zephyr/boards/tdk/robokit1/robokit1-pinctrl.dtsi:129 */
			uart3_default: uart3_default {

				/* node '/soc/pinctrl@400e0e00/uart3_default/group1' defined in zephyr/boards/tdk/robokit1/robokit1-pinctrl.dtsi:130 */
				group1 {
					pinmux = < 0x3c3 >,
					         < 0x3e3 >; /* in zephyr/boards/tdk/robokit1/robokit1-pinctrl.dtsi:131 */
				};
			};

			/* node '/soc/pinctrl@400e0e00/uart4_default' defined in zephyr/boards/tdk/robokit1/robokit1-pinctrl.dtsi:136 */
			uart4_default: uart4_default {

				/* node '/soc/pinctrl@400e0e00/uart4_default/group1' defined in zephyr/boards/tdk/robokit1/robokit1-pinctrl.dtsi:137 */
				group1 {
					pinmux = < 0x2333 >,
					         < 0x2323 >; /* in zephyr/boards/tdk/robokit1/robokit1-pinctrl.dtsi:138 */
				};
			};

			/* node '/soc/pinctrl@400e0e00/usart0_default' defined in zephyr/boards/tdk/robokit1/robokit1-pinctrl.dtsi:143 */
			usart0_default: usart0_default {

				/* node '/soc/pinctrl@400e0e00/usart0_default/group1' defined in zephyr/boards/tdk/robokit1/robokit1-pinctrl.dtsi:144 */
				group1 {
					pinmux = < 0x2201 >,
					         < 0x2211 >; /* in zephyr/boards/tdk/robokit1/robokit1-pinctrl.dtsi:145 */
				};
			};

			/* node '/soc/pinctrl@400e0e00/usart0_hw_ctrl_flow_clk' defined in zephyr/boards/tdk/robokit1/robokit1-pinctrl.dtsi:150 */
			usart0_hw_ctrl_flow_clk: usart0_hw_ctrl_flow_clk {

				/* node '/soc/pinctrl@400e0e00/usart0_hw_ctrl_flow_clk/group1' defined in zephyr/boards/tdk/robokit1/robokit1-pinctrl.dtsi:151 */
				group1 {
					pinmux = < 0x2201 >,
					         < 0x2231 >; /* in zephyr/boards/tdk/robokit1/robokit1-pinctrl.dtsi:152 */
					bias-pull-up;        /* in zephyr/boards/tdk/robokit1/robokit1-pinctrl.dtsi:154 */
				};

				/* node '/soc/pinctrl@400e0e00/usart0_hw_ctrl_flow_clk/group2' defined in zephyr/boards/tdk/robokit1/robokit1-pinctrl.dtsi:157 */
				group2 {
					pinmux = < 0x2211 >,
					         < 0x2221 >,
					         < 0x22d1 >; /* in zephyr/boards/tdk/robokit1/robokit1-pinctrl.dtsi:158 */
				};
			};

			/* node '/soc/pinctrl@400e0e00/usart1_default' defined in zephyr/boards/tdk/robokit1/robokit1-pinctrl.dtsi:164 */
			usart1_default: usart1_default {

				/* node '/soc/pinctrl@400e0e00/usart1_default/group1' defined in zephyr/boards/tdk/robokit1/robokit1-pinctrl.dtsi:165 */
				group1 {
					pinmux = < 0x350 >,
					         < 0x3241 >; /* in zephyr/boards/tdk/robokit1/robokit1-pinctrl.dtsi:166 */
				};
			};

			/* node '/soc/pinctrl@400e0e00/usart1_hw_ctrl_flow' defined in zephyr/boards/tdk/robokit1/robokit1-pinctrl.dtsi:171 */
			usart1_hw_ctrl_flow: usart1_hw_ctrl_flow {

				/* node '/soc/pinctrl@400e0e00/usart1_hw_ctrl_flow/group1' defined in zephyr/boards/tdk/robokit1/robokit1-pinctrl.dtsi:172 */
				group1 {
					pinmux = < 0x350 >,
					         < 0x380 >; /* in zephyr/boards/tdk/robokit1/robokit1-pinctrl.dtsi:173 */
					bias-pull-up;       /* in zephyr/boards/tdk/robokit1/robokit1-pinctrl.dtsi:175 */
				};

				/* node '/soc/pinctrl@400e0e00/usart1_hw_ctrl_flow/group2' defined in zephyr/boards/tdk/robokit1/robokit1-pinctrl.dtsi:178 */
				group2 {
					pinmux = < 0x3241 >,
					         < 0x390 >;  /* in zephyr/boards/tdk/robokit1/robokit1-pinctrl.dtsi:179 */
				};
			};

			/* node '/soc/pinctrl@400e0e00/usart2_default' defined in zephyr/boards/tdk/robokit1/robokit1-pinctrl.dtsi:184 */
			usart2_default: usart2_default {
				phandle = < 0xa >; /* in zephyr/boards/tdk/robokit1/robokit1-common.dtsi:170 */

				/* node '/soc/pinctrl@400e0e00/usart2_default/group1' defined in zephyr/boards/tdk/robokit1/robokit1-pinctrl.dtsi:185 */
				group1 {
					pinmux = < 0x12f3 >,
					         < 0x1303 >; /* in zephyr/boards/tdk/robokit1/robokit1-pinctrl.dtsi:186 */
				};
			};

			/* node '/soc/pinctrl@400e0e00/usart2_hw_ctrl_flow_clk' defined in zephyr/boards/tdk/robokit1/robokit1-pinctrl.dtsi:191 */
			usart2_hw_ctrl_flow_clk: usart2_hw_ctrl_flow_clk {

				/* node '/soc/pinctrl@400e0e00/usart2_hw_ctrl_flow_clk/group1' defined in zephyr/boards/tdk/robokit1/robokit1-pinctrl.dtsi:192 */
				group1 {
					pinmux = < 0x12f3 >,
					         < 0x1323 >; /* in zephyr/boards/tdk/robokit1/robokit1-pinctrl.dtsi:193 */
					bias-pull-up;        /* in zephyr/boards/tdk/robokit1/robokit1-pinctrl.dtsi:195 */
				};

				/* node '/soc/pinctrl@400e0e00/usart2_hw_ctrl_flow_clk/group2' defined in zephyr/boards/tdk/robokit1/robokit1-pinctrl.dtsi:198 */
				group2 {
					pinmux = < 0x1303 >,
					         < 0x1333 >,
					         < 0x1313 >; /* in zephyr/boards/tdk/robokit1/robokit1-pinctrl.dtsi:199 */
				};
			};
		};

		/* node '/soc/rstc@400e1800' defined in zephyr/dts/arm/atmel/samx7x.dtsi:430 */
		rstc: rstc@400e1800 {
			compatible = "atmel,sam-rstc"; /* in zephyr/dts/arm/atmel/samx7x.dtsi:431 */
			reg = < 0x400e1800 0x10 >;     /* in zephyr/dts/arm/atmel/samx7x.dtsi:432 */
			clocks = < &pmc 0x2 0x1 >;     /* in zephyr/dts/arm/atmel/samx7x.dtsi:433 */
			user-nrst;                     /* in zephyr/dts/arm/atmel/samx7x.dtsi:434 */
		};

		/* node '/soc/supc@400e1810' defined in zephyr/dts/arm/atmel/samx7x.dtsi:437 */
		supc: supc@400e1810 {
			compatible = "atmel,sam-supc";     /* in zephyr/dts/arm/atmel/samx7x.dtsi:438 */
			reg = < 0x400e1810 0x20 >;         /* in zephyr/dts/arm/atmel/samx7x.dtsi:439 */
			#wakeup-source-id-cells = < 0x1 >; /* in zephyr/dts/arm/atmel/samx7x.dtsi:440 */
			status = "okay";                   /* in zephyr/dts/arm/atmel/samx7x.dtsi:441 */
		};

		/* node '/soc/watchdog@400e1850' defined in zephyr/dts/arm/atmel/samx7x.dtsi:444 */
		wdt: watchdog@400e1850 {
			compatible = "atmel,sam-watchdog"; /* in zephyr/dts/arm/atmel/samx7x.dtsi:445 */
			reg = < 0x400e1850 0xc >;          /* in zephyr/dts/arm/atmel/samx7x.dtsi:446 */
			interrupts = < 0x4 0x0 >;          /* in zephyr/dts/arm/atmel/samx7x.dtsi:447 */
			clocks = < &pmc 0x2 0x4 >;         /* in zephyr/dts/arm/atmel/samx7x.dtsi:448 */
			status = "okay";                   /* in zephyr/boards/tdk/robokit1/robokit1-common.dtsi:176 */
		};

		/* node '/soc/rtc@400e1860' defined in zephyr/dts/arm/atmel/samx7x.dtsi:452 */
		rtc: rtc@400e1860 {
			compatible = "atmel,sam-rtc"; /* in zephyr/dts/arm/atmel/samx7x.dtsi:453 */
			reg = < 0x400e1860 0x100 >;   /* in zephyr/dts/arm/atmel/samx7x.dtsi:454 */
			interrupts = < 0x2 0x0 >;     /* in zephyr/dts/arm/atmel/samx7x.dtsi:455 */
			clocks = < &pmc 0x2 0x2 >;    /* in zephyr/dts/arm/atmel/samx7x.dtsi:456 */
			alarms-count = < 0x1 >;       /* in zephyr/dts/arm/atmel/samx7x.dtsi:457 */
			status = "disabled";          /* in zephyr/dts/arm/atmel/samx7x.dtsi:458 */
		};

		/* node '/soc/uart@400e1a00' defined in zephyr/dts/arm/atmel/samx7x.dtsi:461 */
		uart2: uart@400e1a00 {
			compatible = "atmel,sam-uart";  /* in zephyr/dts/arm/atmel/samx7x.dtsi:462 */
			reg = < 0x400e1a00 0x100 >;     /* in zephyr/dts/arm/atmel/samx7x.dtsi:463 */
			interrupts = < 0x2c 0x1 >;      /* in zephyr/dts/arm/atmel/samx7x.dtsi:464 */
			clocks = < &pmc 0x2 0x2c >;     /* in zephyr/dts/arm/atmel/samx7x.dtsi:465 */
			current-speed = < 0x1c200 >;    /* in zephyr/boards/tdk/robokit1/robokit1-common.dtsi:162 */
			pinctrl-0 = < &uart2_default >; /* in zephyr/boards/tdk/robokit1/robokit1-common.dtsi:163 */
			pinctrl-names = "default";      /* in zephyr/boards/tdk/robokit1/robokit1-common.dtsi:164 */
			status = "okay";                /* in zephyr/boards/tdk/robokit1/robokit1-common.dtsi:165 */
		};

		/* node '/soc/uart@400e1c00' defined in zephyr/dts/arm/atmel/samx7x.dtsi:469 */
		uart3: uart@400e1c00 {
			compatible = "atmel,sam-uart"; /* in zephyr/dts/arm/atmel/samx7x.dtsi:470 */
			reg = < 0x400e1c00 0x100 >;    /* in zephyr/dts/arm/atmel/samx7x.dtsi:471 */
			interrupts = < 0x2d 0x1 >;     /* in zephyr/dts/arm/atmel/samx7x.dtsi:472 */
			clocks = < &pmc 0x2 0x2d >;    /* in zephyr/dts/arm/atmel/samx7x.dtsi:473 */
			status = "disabled";           /* in zephyr/dts/arm/atmel/samx7x.dtsi:474 */
		};

		/* node '/soc/uart@400e1e00' defined in zephyr/dts/arm/atmel/samx7x.dtsi:477 */
		uart4: uart@400e1e00 {
			compatible = "atmel,sam-uart"; /* in zephyr/dts/arm/atmel/samx7x.dtsi:478 */
			reg = < 0x400e1e00 0x100 >;    /* in zephyr/dts/arm/atmel/samx7x.dtsi:479 */
			interrupts = < 0x2e 0x1 >;     /* in zephyr/dts/arm/atmel/samx7x.dtsi:480 */
			clocks = < &pmc 0x2 0x2e >;    /* in zephyr/dts/arm/atmel/samx7x.dtsi:481 */
			status = "disabled";           /* in zephyr/dts/arm/atmel/samx7x.dtsi:482 */
		};
	};

	/* node '/cpus' defined in zephyr/dts/arm/atmel/samx7x.dtsi:26 */
	cpus {
		#address-cells = < 0x1 >; /* in zephyr/dts/arm/atmel/samx7x.dtsi:27 */
		#size-cells = < 0x0 >;    /* in zephyr/dts/arm/atmel/samx7x.dtsi:28 */

		/* node '/cpus/cpu@0' defined in zephyr/dts/arm/atmel/samx7x.dtsi:30 */
		cpu0: cpu@0 {
			device_type = "cpu";              /* in zephyr/dts/arm/atmel/samx7x.dtsi:31 */
			compatible = "arm,cortex-m7";     /* in zephyr/dts/arm/atmel/samx7x.dtsi:32 */
			reg = < 0x0 >;                    /* in zephyr/dts/arm/atmel/samx7x.dtsi:33 */
			#address-cells = < 0x1 >;         /* in zephyr/dts/arm/atmel/samx7x.dtsi:34 */
			#size-cells = < 0x1 >;            /* in zephyr/dts/arm/atmel/samx7x.dtsi:35 */
			clock-frequency = < 0x11e1a300 >; /* in zephyr/boards/tdk/robokit1/robokit1-common.dtsi:61 */

			/* node '/cpus/cpu@0/mpu@e000ed90' defined in zephyr/dts/arm/atmel/samx7x.dtsi:37 */
			mpu: mpu@e000ed90 {
				compatible = "arm,armv7m-mpu"; /* in zephyr/dts/arm/atmel/samx7x.dtsi:38 */
				reg = < 0xe000ed90 0x40 >;     /* in zephyr/dts/arm/atmel/samx7x.dtsi:39 */
			};
		};
	};

	/* node '/memory@20400000' defined in zephyr/dts/arm/atmel/samx7x.dtsi:44 */
	sram0: memory@20400000 {
		compatible = "mmio-sram";     /* in zephyr/dts/arm/atmel/samx7x.dtsi:45 */
		reg = < 0x20400000 0x60000 >; /* in zephyr/dts/arm/atmel/samx7xx21.dtsi:12 */
	};

	/* node '/leds' defined in zephyr/boards/tdk/robokit1/robokit1-common.dtsi:26 */
	leds {
		compatible = "gpio-leds"; /* in zephyr/boards/tdk/robokit1/robokit1-common.dtsi:27 */

		/* node '/leds/led_0' defined in zephyr/boards/tdk/robokit1/robokit1-common.dtsi:29 */
		led_0: led_0 {
			gpios = < &pioa 0xb 0x0 >; /* in zephyr/boards/tdk/robokit1/robokit1-common.dtsi:30 */
			label = "User LED";        /* in zephyr/boards/tdk/robokit1/robokit1-common.dtsi:31 */
		};

		/* node '/leds/led_1' defined in zephyr/boards/tdk/robokit1/robokit1-common.dtsi:34 */
		led_1: led_1 {
			gpios = < &pioa 0xc 0x0 >; /* in zephyr/boards/tdk/robokit1/robokit1-common.dtsi:35 */
			label = "User LED";        /* in zephyr/boards/tdk/robokit1/robokit1-common.dtsi:36 */
		};

		/* node '/leds/led_2' defined in zephyr/boards/tdk/robokit1/robokit1-common.dtsi:39 */
		led_2: led_2 {
			gpios = < &pioa 0xd 0x0 >; /* in zephyr/boards/tdk/robokit1/robokit1-common.dtsi:40 */
			label = "User LED";        /* in zephyr/boards/tdk/robokit1/robokit1-common.dtsi:41 */
		};

		/* node '/leds/led_3' defined in zephyr/boards/tdk/robokit1/robokit1-common.dtsi:44 */
		led_3: led_3 {
			gpios = < &pioa 0xe 0x0 >; /* in zephyr/boards/tdk/robokit1/robokit1-common.dtsi:45 */
			label = "User LED";        /* in zephyr/boards/tdk/robokit1/robokit1-common.dtsi:46 */
		};
	};

	/* node '/ambient_temp_sensor' defined in zephyr/boards/tdk/robokit1/robokit1-common.dtsi:50 */
	temp_sensor: ambient_temp_sensor {
		compatible = "epcos,b57861s0103a039"; /* in zephyr/boards/tdk/robokit1/robokit1-common.dtsi:51 */
		io-channels = < &spi_adc 0x0 >;       /* in zephyr/boards/tdk/robokit1/robokit1-common.dtsi:52 */
		pullup-uv = < 0x325aa0 >;             /* in zephyr/boards/tdk/robokit1/robokit1-common.dtsi:53 */
		pullup-ohm = < 0x0 >;                 /* in zephyr/boards/tdk/robokit1/robokit1-common.dtsi:54 */
		pulldown-ohm = < 0x2710 >;            /* in zephyr/boards/tdk/robokit1/robokit1-common.dtsi:55 */
		connected-positive;                   /* in zephyr/boards/tdk/robokit1/robokit1-common.dtsi:56 */
	};
};
